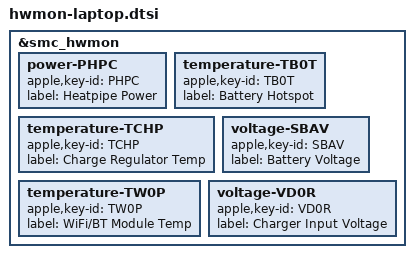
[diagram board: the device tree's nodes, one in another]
// SPDX-License-Identifier: GPL-2.0+ OR MIT
/*
 * hwmon sensors expected on all laptops
 *
 * Copyright The Asahi Linux Contributors
 */

&smc_hwmon {
	power-PHPC {
		apple,key-id = "PHPC";
		label = "Heatpipe Power";
	};

	temperature-TB0T {
		apple,key-id = "TB0T";
		label = "Battery Hotspot";
	};

	temperature-TCHP {
		apple,key-id = "TCHP";
		label = "Charge Regulator Temp";
	};

	temperature-TW0P {
		apple,key-id = "TW0P";
		label = "WiFi/BT Module Temp";
	};

	voltage-SBAV {
		apple,key-id = "SBAV";
		label = "Battery Voltage";
	};

	voltage-VD0R {
		apple,key-id = "VD0R";
		label = "Charger Input Voltage";
	};
};
